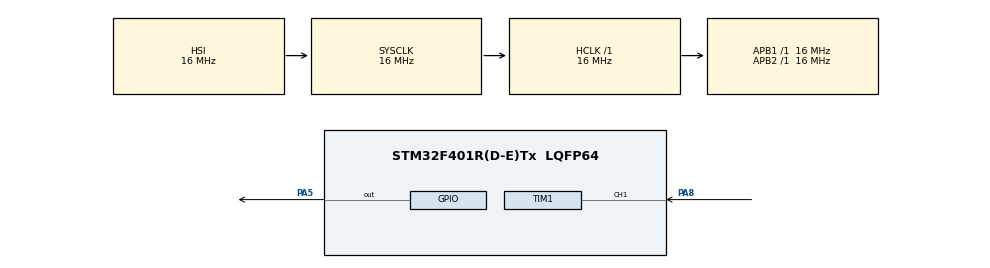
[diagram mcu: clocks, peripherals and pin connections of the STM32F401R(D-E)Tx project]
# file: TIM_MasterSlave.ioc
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Mcu.Family=STM32F4
RCC.CortexFreq_Value=16000000
TIM3.AutoReloadPreload=TIM_AUTORELOAD_PRELOAD_DISABLE
TIM1.Slave_TriggerPolarity=TIM_TRIGGERPOLARITY_RISING
PA5.PinState=GPIO_PIN_RESET
ProjectManager.StackSize=0x400
TIM1.Prescaler=15999
SH.S_TIM1_CH1.0=TIM1_CH1,TriggerSource_TI1FP1
ProjectManager.TargetToolchain=STM32CubeIDE
TIM3.Period=1
VP_TIM3_VS_ControllerModeClock.Mode=Clock Mode
RCC.LSE_VALUE=32768
RCC.AHBFreq_Value=16000000
PA5.Signal=GPIO_Output
RCC.HSE_VALUE=25000000
board=custom
PA8.GPIO_ModeDefaultPP=GPIO_MODE_AF_PP
RCC.VCOOutputFreq_Value=192000000
NVIC.TIM3_IRQn=true\:0\:0\:false\:false\:true\:true\:true
TIM1.TIM_MasterOutputTrigger=TIM_TRGO_UPDATE
RCC.APB2Freq_Value=16000000
PA5.GPIO_PuPd=GPIO_NOPULL
PA8.Signal=S_TIM1_CH1
VP_TIM3_VS_ClockSourceITR.Mode=TriggerSource_ITR0
Mcu.Name=STM32F401R(D-E)Tx
VP_TIM1_VS_ClockSourceINT.Mode=Internal
TIM1.Slave_TriggerFilter=15
RCC.SYSCLKFreq_VALUE=16000000
Mcu.Package=LQFP64
TIM3.TIM_MasterSlaveMode=TIM_MASTERSLAVEMODE_DISABLE
ProjectManager.HeapSize=0x200
RCC.HSI_VALUE=16000000
PA8.GPIO_PuPd=GPIO_PULLDOWN
NVIC.PriorityGroup=NVIC_PRIORITYGROUP_4
TIM1.Period=249
TIM3.TIM_MasterOutputTrigger=TIM_TRGO_RESET
RCC.APB1Freq_Value=16000000
VP_TIM1_VS_ControllerModeTrigger.Mode=Trigger Mode
TIM1.TIM_MasterSlaveMode=TIM_MASTERSLAVEMODE_ENABLE

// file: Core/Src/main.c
/* USER CODE BEGIN Header */
/**
  ******************************************************************************
  * @file           : main.c
  * @brief          : Main program body
  ******************************************************************************
  * @attention
  *
  * <h2><center>&copy; Copyright (c) 2021 STMicroelectronics.
  * All rights reserved.</center></h2>
  *
  * This software component is licensed by ST under BSD 3-Clause license,
  * the "License"; You may not use this file except in compliance with the
  * License. You may obtain a copy of the License at:
  *                        opensource.org/licenses/BSD-3-Clause
  *
  ******************************************************************************
  */
/* USER CODE END Header */
#include "main.h"

TIM_HandleTypeDef htim1;
TIM_HandleTypeDef htim3;

void SystemClock_Config(void);
static void MX_GPIO_Init(void);
static void MX_TIM1_Init(void);
static void MX_TIM3_Init(void);

int main(void)
{

  /* MCU Configuration--------------------------------------------------------*/

  /* Reset of all peripherals, Initializes the Flash interface and the Systick. */
  HAL_Init();

  /* Configure the system clock */
  SystemClock_Config();

  /* Initialize all configured peripherals */
  MX_GPIO_Init();
  MX_TIM1_Init();
  MX_TIM3_Init();
  /* USER CODE BEGIN 2 */
  HAL_TIM_Base_Start_IT(&htim3);
  /* USER CODE END 2 */

  /* Infinite loop */
  while (1)
  {

  }
}

void SystemClock_Config(void)
{
  RCC_OscInitTypeDef RCC_OscInitStruct = {0};
  RCC_ClkInitTypeDef RCC_ClkInitStruct = {0};

  /** Configure the main internal regulator output voltage
  */
  __HAL_RCC_PWR_CLK_ENABLE();
  __HAL_PWR_VOLTAGESCALING_CONFIG(PWR_REGULATOR_VOLTAGE_SCALE2);
  /** Initializes the RCC Oscillators according to the specified parameters
  * in the RCC_OscInitTypeDef structure.
  */
  RCC_OscInitStruct.OscillatorType = RCC_OSCILLATORTYPE_HSI;
  RCC_OscInitStruct.HSIState = RCC_HSI_ON;
  RCC_OscInitStruct.HSICalibrationValue = RCC_HSICALIBRATION_DEFAULT;
  RCC_OscInitStruct.PLL.PLLState = RCC_PLL_NONE;
  if (HAL_RCC_OscConfig(&RCC_OscInitStruct) != HAL_OK)
  {
    Error_Handler();
  }
  /** Initializes the CPU, AHB and APB buses clocks
  */
  RCC_ClkInitStruct.ClockType = RCC_CLOCKTYPE_HCLK|RCC_CLOCKTYPE_SYSCLK
                              |RCC_CLOCKTYPE_PCLK1|RCC_CLOCKTYPE_PCLK2;
  RCC_ClkInitStruct.SYSCLKSource = RCC_SYSCLKSOURCE_HSI;
  RCC_ClkInitStruct.AHBCLKDivider = RCC_SYSCLK_DIV1;
  RCC_ClkInitStruct.APB1CLKDivider = RCC_HCLK_DIV1;
  RCC_ClkInitStruct.APB2CLKDivider = RCC_HCLK_DIV1;

  if (HAL_RCC_ClockConfig(&RCC_ClkInitStruct, FLASH_LATENCY_0) != HAL_OK)
  {
    Error_Handler();
  }
}

static void MX_TIM1_Init(void)
{

  TIM_ClockConfigTypeDef sClockSourceConfig = {0};
  TIM_SlaveConfigTypeDef sSlaveConfig = {0};
  TIM_MasterConfigTypeDef sMasterConfig = {0};

  htim1.Instance = TIM1;
  htim1.Init.Prescaler = 15999;
  htim1.Init.CounterMode = TIM_COUNTERMODE_UP;
  htim1.Init.Period = 249;
  htim1.Init.ClockDivision = TIM_CLOCKDIVISION_DIV1;
  htim1.Init.RepetitionCounter = 0;
  htim1.Init.AutoReloadPreload = TIM_AUTORELOAD_PRELOAD_DISABLE;
  if (HAL_TIM_Base_Init(&htim1) != HAL_OK)
  {
    Error_Handler();
  }
  sClockSourceConfig.ClockSource = TIM_CLOCKSOURCE_INTERNAL;
  if (HAL_TIM_ConfigClockSource(&htim1, &sClockSourceConfig) != HAL_OK)
  {
    Error_Handler();
  }
  sSlaveConfig.SlaveMode = TIM_SLAVEMODE_TRIGGER;
  sSlaveConfig.InputTrigger = TIM_TS_TI1FP1;
  sSlaveConfig.TriggerPolarity = TIM_TRIGGERPOLARITY_RISING;
  sSlaveConfig.TriggerFilter = 15;
  if (HAL_TIM_SlaveConfigSynchro(&htim1, &sSlaveConfig) != HAL_OK)
  {
    Error_Handler();
  }
  sMasterConfig.MasterOutputTrigger = TIM_TRGO_UPDATE;
  sMasterConfig.MasterSlaveMode = TIM_MASTERSLAVEMODE_ENABLE;
  if (HAL_TIMEx_MasterConfigSynchronization(&htim1, &sMasterConfig) != HAL_OK)
  {
    Error_Handler();
  }

}

static void MX_TIM3_Init(void)
{

  TIM_SlaveConfigTypeDef sSlaveConfig = {0};
  TIM_MasterConfigTypeDef sMasterConfig = {0};

  htim3.Instance = TIM3;
  htim3.Init.Prescaler = 0;
  htim3.Init.CounterMode = TIM_COUNTERMODE_UP;
  htim3.Init.Period = 1;
  htim3.Init.ClockDivision = TIM_CLOCKDIVISION_DIV1;
  htim3.Init.AutoReloadPreload = TIM_AUTORELOAD_PRELOAD_DISABLE;
  if (HAL_TIM_Base_Init(&htim3) != HAL_OK)
  {
    Error_Handler();
  }
  sSlaveConfig.SlaveMode = TIM_SLAVEMODE_EXTERNAL1;
  sSlaveConfig.InputTrigger = TIM_TS_ITR0;
  if (HAL_TIM_SlaveConfigSynchro(&htim3, &sSlaveConfig) != HAL_OK)
  {
    Error_Handler();
  }
  sMasterConfig.MasterOutputTrigger = TIM_TRGO_RESET;
  sMasterConfig.MasterSlaveMode = TIM_MASTERSLAVEMODE_DISABLE;
  if (HAL_TIMEx_MasterConfigSynchronization(&htim3, &sMasterConfig) != HAL_OK)
  {
    Error_Handler();
  }

}

static void MX_GPIO_Init(void)
{
  GPIO_InitTypeDef GPIO_InitStruct = {0};

  /* GPIO Ports Clock Enable */
  __HAL_RCC_GPIOA_CLK_ENABLE();

  /*Configure GPIO pin Output Level */
  HAL_GPIO_WritePin(GPIOA, GPIO_PIN_5, GPIO_PIN_SET);

  /*Configure GPIO pin : PA5 */
  GPIO_InitStruct.Pin = GPIO_PIN_5;
  GPIO_InitStruct.Mode = GPIO_MODE_OUTPUT_PP;
  GPIO_InitStruct.Pull = GPIO_NOPULL;
  GPIO_InitStruct.Speed = GPIO_SPEED_FREQ_LOW;
  HAL_GPIO_Init(GPIOA, &GPIO_InitStruct);

}

/* USER CODE BEGIN 4 */
void HAL_TIM_PeriodElapsedCallback(TIM_HandleTypeDef *htim) {
  if(htim->Instance == TIM3)
    HAL_GPIO_TogglePin(GPIOA, GPIO_PIN_5);
}
/* USER CODE END 4 */

void Error_Handler(void)
{
  __disable_irq();
  while (1)
  {
  }
}

/************************ (C) COPYRIGHT STMicroelectronics *****END OF FILE****/
